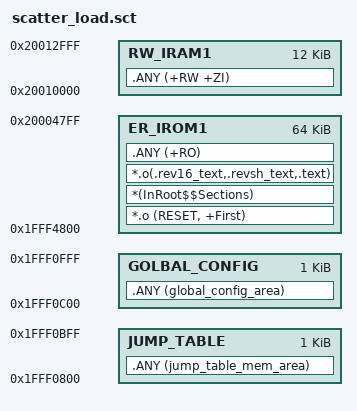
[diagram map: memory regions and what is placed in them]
; *************************************************************
; *** Scatter-Loading Description File generated by uVision ***
; *************************************************************

 LR_IROM1 0x1fff4800 0x00010000 {  ; load region size_region
  ER_IROM1 0x1fff4800 0x00010000  {  ; load address = execution address
   *.o (RESET, +First)
   *(InRoot$$Sections)
   *.o(.rev16_text,.revsh_text,.text)
   .ANY (+RO) 
  }
  
  RW_IRAM1 0x20010000 0x00003000  {  ; RW data
   .ANY (+RW +ZI)
  }
  ;ER_IROM2 0x1fff4100 0x0003500  {  ; load address = execution address
  ; .ANY (+RO) 
  ;}  
  
  ;RW_IRAM1 0x1fff7600 0x00000d00  {  ; RW data
  ; .ANY (+RW +ZI)
  ;}
 
}
 
LR_IROM2  0x1fff0800 0x00800 {
  JUMP_TABLE 0x1fff0800 0x00400  {
   .ANY (jump_table_mem_area) 
	
  }
  GOLBAL_CONFIG 0x1fff0c00 0x00400  {
   .ANY (global_config_area) 
	
  }  
 } 



